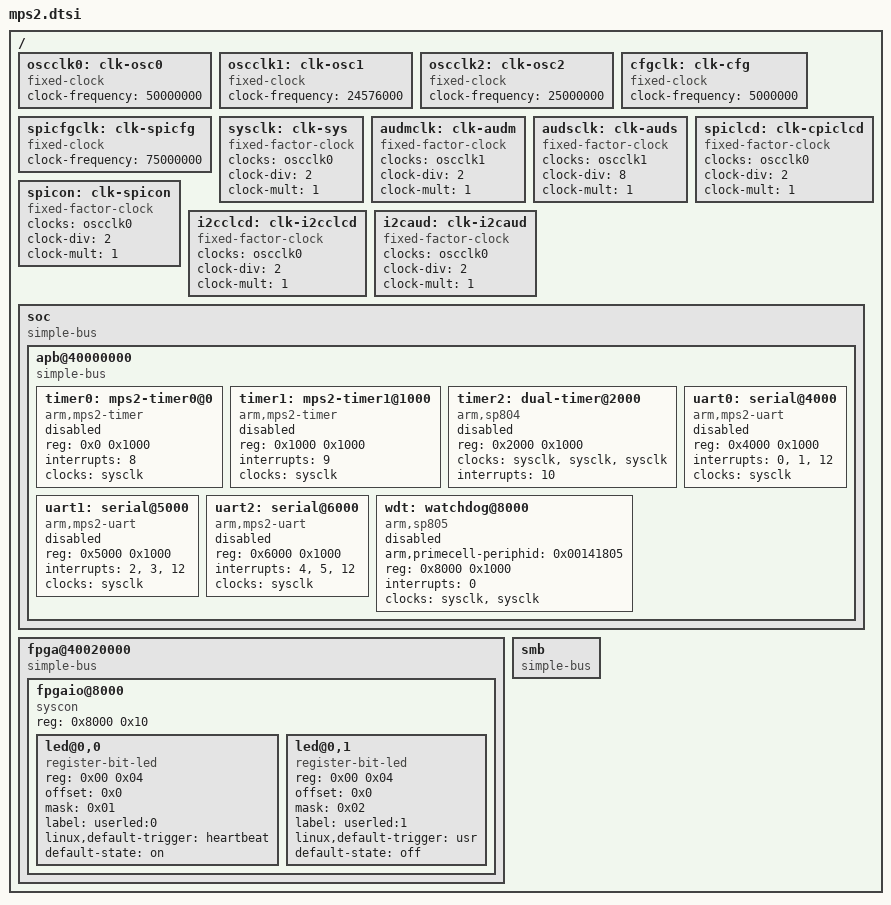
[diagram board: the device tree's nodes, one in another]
#include "../armv7-m.dtsi"
/ {
	#address-cells = <1>;
	#size-cells = <1>;
	oscclk0: clk-osc0 {
		compatible = "fixed-clock";
		#clock-cells = <0>;
		clock-frequency = <50000000>;
	};
	oscclk1: clk-osc1 {
		compatible = "fixed-clock";
		#clock-cells = <0>;
		clock-frequency = <24576000>;
	};
	oscclk2: clk-osc2 {
		compatible = "fixed-clock";
		#clock-cells = <0>;
		clock-frequency = <25000000>;
	};
	cfgclk: clk-cfg {
		compatible = "fixed-clock";
		#clock-cells = <0>;
		clock-frequency = <5000000>;
	};
	spicfgclk: clk-spicfg {
		compatible = "fixed-clock";
		#clock-cells = <0>;
		clock-frequency = <75000000>;
	};
	sysclk: clk-sys {
		compatible = "fixed-factor-clock";
		clocks = <&oscclk0>;
		#clock-cells = <0>;
		clock-div = <2>;
		clock-mult = <1>;
	};
	audmclk: clk-audm {
		compatible = "fixed-factor-clock";
		clocks = <&oscclk1>;
		#clock-cells = <0>;
		clock-div = <2>;
		clock-mult = <1>;
	};
	audsclk: clk-auds {
		compatible = "fixed-factor-clock";
		clocks = <&oscclk1>;
		#clock-cells = <0>;
		clock-div = <8>;
		clock-mult = <1>;
	};
	spiclcd: clk-cpiclcd {
		compatible = "fixed-factor-clock";
		clocks = <&oscclk0>;
		#clock-cells = <0>;
		clock-div = <2>;
		clock-mult = <1>;
	};
	spicon: clk-spicon {
		compatible = "fixed-factor-clock";
		clocks = <&oscclk0>;
		#clock-cells = <0>;
		clock-div = <2>;
		clock-mult = <1>;
	};
	i2cclcd: clk-i2cclcd {
		compatible = "fixed-factor-clock";
		clocks = <&oscclk0>;
		#clock-cells = <0>;
		clock-div = <2>;
		clock-mult = <1>;
	};
	i2caud: clk-i2caud {
		compatible = "fixed-factor-clock";
		clocks = <&oscclk0>;
		#clock-cells = <0>;
		clock-div = <2>;
		clock-mult = <1>;
	};
	soc {
		compatible = "simple-bus";
		ranges;
		apb@40000000 {
			compatible = "simple-bus";
			#address-cells = <1>;
			#size-cells = <1>;
			ranges = <0 0x40000000 0x10000>;
			timer0: mps2-timer0@0 {
				compatible = "arm,mps2-timer";
				reg = <0x0 0x1000>;
				interrupts = <8>;
				clocks = <&sysclk>;
				status = "disabled";
			};
			timer1: mps2-timer1@1000 {
				compatible = "arm,mps2-timer";
				reg = <0x1000 0x1000>;
				interrupts = <9>;
				clocks = <&sysclk>;
				status = "disabled";
			};
			timer2: dual-timer@2000 {
				compatible = "arm,sp804", "arm,primecell";
				reg = <0x2000 0x1000>;
				clocks = <&sysclk>, <&sysclk>, <&sysclk>;
				clock-names = "timer0clk", "timer1clk",
					       "apb_pclk";
				interrupts = <10>;
				status = "disabled";
			};
			uart0: serial@4000 {
				compatible = "arm,mps2-uart";
				reg = <0x4000 0x1000>;
				interrupts = <0>, <1>, <12>;
				clocks = <&sysclk>;
				status = "disabled";
			};
			uart1: serial@5000 {
				compatible = "arm,mps2-uart";
				reg = <0x5000 0x1000>;
				interrupts = <2>, <3>, <12>;
				clocks = <&sysclk>;
				status = "disabled";
			};
			uart2: serial@6000 {
				compatible = "arm,mps2-uart";
				reg = <0x6000 0x1000>;
				interrupts = <4>, <5>, <12>;
				clocks = <&sysclk>;
				status = "disabled";
			};
			wdt: watchdog@8000 {
				compatible = "arm,sp805", "arm,primecell";
				arm,primecell-periphid = <0x00141805>;
				reg = <0x8000 0x1000>;
				interrupts = <0>;
				clocks = <&sysclk>, <&sysclk>;
				clock-names = "wdog_clk", "apb_pclk";
				status = "disabled";
			};
		};
	};
	fpga@40020000 {
		compatible = "simple-bus";
		#address-cells = <1>;
		#size-cells = <1>;
		ranges = <0 0x40020000 0x10000>;
		fpgaio@8000 {
			compatible = "syscon", "simple-mfd";
			reg = <0x8000 0x10>;
			ranges = <0x0 0x8000 0x10>;
			#address-cells = <1>;
			#size-cells = <1>;
			led@0,0 {
				compatible = "register-bit-led";
				reg = <0x00 0x04>;
				offset = <0x0>;
				mask = <0x01>;
				label = "userled:0";
				linux,default-trigger = "heartbeat";
				default-state = "on";
			};
			led@0,1 {
				compatible = "register-bit-led";
				reg = <0x00 0x04>;
				offset = <0x0>;
				mask = <0x02>;
				label = "userled:1";
				linux,default-trigger = "usr";
				default-state = "off";
			};
		};
	};
	smb {
		compatible = "simple-bus";
		#address-cells = <2>;
		#size-cells = <1>;
		ranges = <0 0 0x40200000 0x10000>,
			 <1 0 0xa0000000 0x10000>;
	};
};
